# psc3m6 register map
Vendor: Infineon Technologies; Series: PSC3M6; File version: 1.0
CPU: CM33 r0p1, little endian, MPU, FPU, DSP, VTOR, 3 interrupt priority bits, 167 interrupts
Registers are 32-bit, read-write, reset 0x0 unless marked. A register's access mark holds for its fields unless they carry their own. Offsets are from the block's base; [hi:lo] are bit positions; lines under a group give offsets from that group; <NAME> marks a mode.

## I3C0 (part 2 of 3) — I3C controller top
Base 0x42C10000
0x00 CORE group — registers in I3C IP core
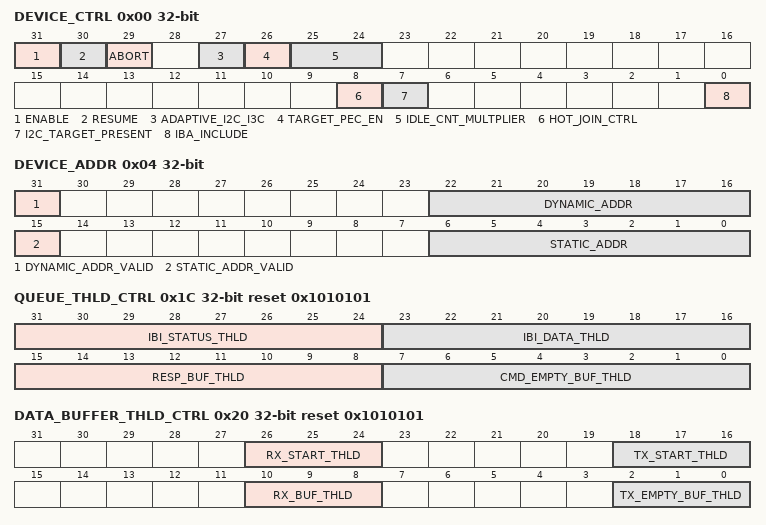
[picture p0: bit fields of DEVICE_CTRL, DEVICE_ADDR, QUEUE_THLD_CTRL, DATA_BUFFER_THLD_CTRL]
  0x00 DEVICE_CTRL — Device Control Register
    [31] ENABLE — I3C Enable Controls whether or not I3C functionality is enabled. When functioning as the Active Controller, software can write to this register to request to disable the I3C block. However, the block may not get disabled immediately and is 'Disabled' after commands in the Command queue (if any) are executed leading to a STOP condition on the bus and Controller FSM is in IDLE state (as indicated by PRESENT_STATE Register). When functioning as a Target, software can write to this register to request to disable the I3C block. However, the disable happens after the ongoing transfer is completed on the I3C bus. Software can read back 1'b0 from this field once disabling of I3C is completed. After power on reset, the software can enable I3C Secondary Controller or Target functionality by programming this bit to 1'b1. However the I3C bus interface of the block will respond to transfer on the bus, only after it observes Bus Available condition for BUS_AVAILABLE_TIME*IDLE_CNT_MULTPLIER counts of pclk period. The successful completion of Enable/Disable of the block depends on availability of SCL to the controller at the time of performing this operation, and hence may not happen instantly. Values: 0x0: Disables the I3C controller. 0x1: Enables the I3C controller.
    [30] RESUME — I3C Resume This bit is used to resume the I3C block after it goes to the Halt state. When functioning as the Active Controller, the block goes to the halt state (as indicated in PRESENT_STATE Register) due to any type of error in the transfer (the type of error is indicated by ERR_STATUS field in the RESPONSE_QUEUE_PORT register). After the block goes to the Halt state, the application has to write 1'b1 to this bit to resume. This bit is auto-cleared once the block resumes the transfers by initiating the next command. When functioning as a Target, the block goes to the halt state due to following conditions: 1 => Any type of error in the transfer (the type of error is indicated by ERR_STATUS field in the RESPONSE_QUEUE_PORT register) 2 => MRL Register updated by the Active Controller through SETMRL CCC. After the device has gone to halt state, the application has to take necessary action to handle the error condition and then write 1'b1 to this bit to resume the controller. This bit is auto-cleared once the controller is ready to accept new transfers.
    [29] ABORT — I3C Abort. This bit is only valid when this I3C Device is functioning as the Active Controller. This bit allows this device to relinquish the I3C Bus before completing the issued transfer. In response to an ABORT request, the Controller issues the STOP condition after the complete data byte is transferred or received. This bit is auto-cleared once the transfer is aborted and the controller issues a 'Transfer Abort' interrupt.
    [27] ADAPTIVE_I2C_I3C — Hot-Join Control for Adaptive I2C/I3C Mode This bit is only valid when this I3C Device is functioning as a Target. In Adaptive Mode, this bit is used to enable some features of this target device. This bit is cleared automatically if the controller determines the mode as I3C. Values: 0x0: The device initiates a Hot-Join without determining the bus mode and assuming itself to be on I3C bus. 0x1: The device initiates a Hot-Join request only after it has switched to I3C mode of operation.
    [26] TARGET_PEC_EN
    [25:24] IDLE_CNT_MULTPLIER — Idle count multiplier. This bit is only valid when this I3C Device is functioning as a Target. After power-on reset, this Target is enabled only after it sees both SDA and SCL lines idle for a specified time. This idle time is calculated by multipliying IDLE_CNT_MULTPLIER with BUS_AVAILABLE_TIME field in the BUS_FREE_AVAIL_TIMING register. Values: 0x00: BUS_AVAILABLE_TIME * 1 0x01: BUS_AVAILABLE_TIME * 2 0x10: BUS_AVAILABLE_TIME * 4 0x11: BUS_AVAILABLE_TIME * 8
    [8] HOT_JOIN_CTRL — Hot-Join ACK/NACK Control This bit is only valid when this I3C Device is functioning as the Active Controller. This bit acts as a global control to ACK/NACK the Hot-Join request from the devices. The Active Controller ACK/NACKs the Hot-Join request from other devices connected on the I3C Bus, based on programming of this bit. Values: 0x0: ACK the Hot-Join request. 0x1: NACK and send broadcast CCC(auto-disable) to disable Hot-join.
    [7] I2C_TARGET_PRESENT — <HIDDEN>
    [0] IBA_INCLUDE — I3C Broadcast Address Include. This bit is only valid when this I3C Device is functioning as the Active Controller. This bit is used to include the I3C broadcast address (0x7E) in private transfers. Note: If the I3C broadcast address is not included in private transfers, In-band Interrupts (IBI) driven from Targets might not win address arbitration and IBIs will get delayed. Values: 0x0: I3C Broadcast Address is not included in Private Transfers 0x1: I3C Broadcast Address is included in Private Transfers
  0x04 DEVICE_ADDR — Device Address Register
    [31] DYNAMIC_ADDR_VALID — Dynamic Address Valid This bit is used to control whether the DYNAMIC_ADDR is valid or not. =>When functioning as the Primary Controller, the user/application must set this bit to 1 along with the DYNAMIC_ADDR. =>When functioning as a Target, the block sets this bit to 1 when the Active Controller assigns the Dynamic address during ENTDAA or SETDASA mechanism. + Values: 0x0: Dynamic Address is invalid 0x1: Dynamic Address is valid
    [22:16] DYNAMIC_ADDR — Device Dynamic Address. This field is used to program the Device Dynamic Address. The block uses this address for I3C transfers. => When functioning as the Primary Controller, the user/application must program the Dynamic Address. => When functioning as a Target, the Active Controller assigns this address during ENTDAA or SETDASA procedures.
    [15] STATIC_ADDR_VALID — Static Address Valid. This field is only valid when this I3C Device is functioning as a Target. Values: 0x0: Static Address in STATIC_ADDR field is invalid 0x1: Static Address in STATIC_ADDR field is valid
    [6:0] STATIC_ADDR — Device Static Address. This field is only valid when this I3C Device is functioning as a Target. The device uses this address to respond to SETDASA CCC Command to get the Dynamic Address if static address is valid (STATIC_ADDRESS_VALID must be set to 1).
  0x0C COMMAND_QUEUE_PORT wo reset not defined
    [31:0] COMMAND — 32-bit Command
  0x10 RESPONSE_QUEUE_PORT ro
    [31:0] RESPONSE — 32-bit Response
  0x14 TX_RX_DATA_PORT — Transmit/Receive Data Port Register
    [31:0] TX_RX_DATA_PORT — Transmit Data Port for write access and Receive Data Port for read access. This field is mapped to the TX Data Buffer when writing and to the RX Data Buffer when reading. The data is always packed in 4-byte aligned data words. If the command length is not aligned to the 4-bytes, then the additional data bytes have to be ignored.
  0x18 IBI_QUEUE_DATA ro — In-Band Interrupt Queue Data Register
    [31:0] IBI_DATA — In-Band Interrupt Data This register is mapped to the IBI Queue. The IBI Data is always packed in 4-byte aligned and put to the IBI Queue. If the incoming data is not aligned to the 4-bytes, then there are unused bytes in the end location of the IBI transfer.
  0x1C QUEUE_THLD_CTRL reset 0x1010101 — Queue Threshold Control Register
    [31:24] IBI_STATUS_THLD — In-Band Interrupt Status Threshold Value. This field controls the number of IBI status entries (or greater) in the IBI queue that trigger the IBI_THLD_STAT interrupt. Every In Band Interrupt received (with or without Payload) by the block generates an IBI status. The application should program only valid values. NOTE: The valid value is only 0 if IBI with payload is selected in the configuration. Values: 0x0 <= N < 16: Interrupt will trigger when queue has N+1 valid entries.
    [23:16] IBI_DATA_THLD
    [15:8] RESP_BUF_THLD — Response Buffer Threshold Value. Controls the minimum number of valid entries in the Response Queue that trigger the RESP_READY_STAT_INTR interrupt. The application should programs only valid values. Values: 0x0 <= N < 8: Interrupt will trigger when queue has N+1 valid entries.
    [7:0] CMD_EMPTY_BUF_THLD — Command Buffer Empty Threshold Value Controls the minimum number of empty locations in the Command Queue that trigger the CMD_QUEUE_READY_STAT interrupt. The application should programs only valid values. Values: 0x0: Interrupt will trigger when the queue is completely empty 0x0 < N < 16: Interrupt will trigger when queue has N empty locations.
  0x20 DATA_BUFFER_THLD_CTRL reset 0x1010101 — Data Buffer Threshold Control Register
    [26:24] RX_START_THLD — Receive Start Threshold Value. When functioning as the Active Controller, when the controller is set up to initiate a read transfer, it waits until either one of the conditions are met before it initiates the read transfer on the I3C Interface. => Data length (as specified in the command) number of locations are empty in the Receive FIFO. => Threshold number of locations (or more) are empty in the Receive FIFO. When functioning as a Target, the block ACKs a write request from the Active Controller only if threshold number of empty locations(or more) are available in its receive buffer. The supported values for RX_START_THLD are: 0x0: Threshold of at least 1 empty entry 0x1: Threshold of at least 4 empty entries 0x2: Threshold of at least 8 empty entries 0x3: Threshold of at least 16 empty entries 0x4: Threshold of at least 32 empty entries 0x5: Threshold of at least 64 empty entries
    [18:16] TX_START_THLD — Transfer Start Threshold Value. When functioning as the Active Controller, when the Controller is set up to initiate a write transfer, it waits until either one of the following conditions are met before it initiates the write transfer on the I3C Interface. => Data length (as specified in the command) number of locations are filled in the TX FIFO. => Threshold number of entries (or more) are available in the TX FIFO When functioning as a Target, the Target ACKs a read request from the Active Controller only if either one of the following conditions are met. => Data length (as specified in the command) number of locations are filled in the Transmit FIFO => Threshold number of entries (or more) are available in the Transmit FIFO Supported values: 0x0: Threshold of at least 1 valid entry 0x1: Threshold of at least 4 valid entries 0x2: Threshold of at least 8 valid entries 0x3: Threshold of at least 16 valid entries 0x4: Threshold of at least 32 valid entries 0x5: Threshold of at least 64 valid entries
    [10:8] RX_BUF_THLD — Receive Buffer Threshold Value. This field controls the number of valid entries (or above) in the RX FIFO that trigger the RX_THLD_STAT interrupt. If the programmed value is greater than the buffer depth, then threshold is set to IC_RX_BUF_DEPTH. Supported values: 0x0: Interrupt triggers with at least 1 valid entry 0x1: Interrupt triggers with at least 4 valid entries 0x2: Interrupt triggers with at least 8 valid entries 0x3: Interrupt triggers with at least 16 valid entries 0x4: Interrupt triggers with at least 32 valid entries 0x5: Interrupt triggers with at least 64 valid entries
    [2:0] TX_EMPTY_BUF_THLD — Transmit Buffer Empty Threshold Value This field controls the number of empty locations (or above) in the TX FIFO that trigger the TX_THLD_STAT interrupt. If the programmed value is greater than the buffer depth, then threshold is set to IC_TX_BUF_DEPTH. Supported values: 0x0: Interrupt triggers with at least 1 empty entry 0x1: Interrupt triggers with at least 4 empty entries 0x2: Interrupt triggers with at least 8 empty entries 0x3: Interrupt triggers with at least 16 empty entries 0x4: Interrupt triggers with at least 32 empty entries 0x5: Interrupt triggers with at least 64 empty entries
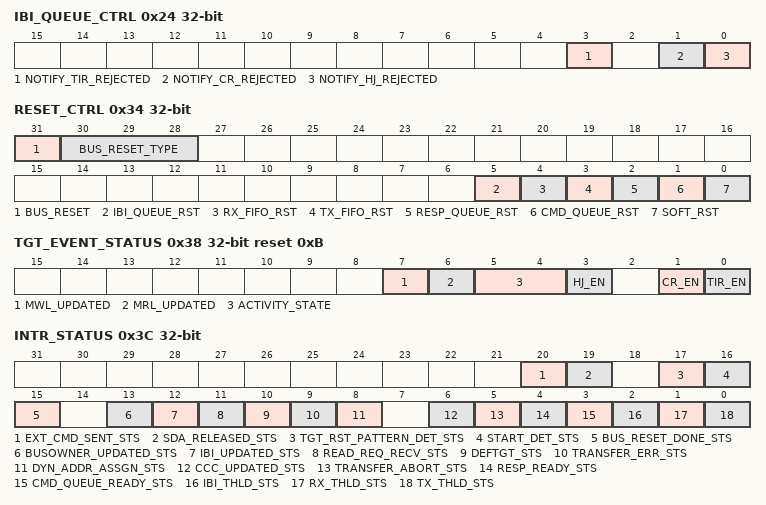
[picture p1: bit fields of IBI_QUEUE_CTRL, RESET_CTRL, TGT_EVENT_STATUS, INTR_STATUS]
  0x24 IBI_QUEUE_CTRL — IBI Queue Control Register
    [3] NOTIFY_TIR_REJECTED — Notify Rejected Target Interrupt Request Control. This bit is only valid when this I3C Device is functioning the Active Controller, and is used to suppress reporting to the application about rejected Target Interrupt Request. Values: 0x0: Disables passing the IBI Status to the IBI FIFO (hence not notifying the application) when a Target Interrupt Request is NACKed and auto-disabled based on the IBI_TIR_REQ_REJECT Register. 0x1: Enables writing the IBI Status to the IBI FIFO (hence notifying the application) when a Target Interrupt Request is NACKed and auto-disabled based on the IBI_TIR_REQ_REJECT Register.
    [1] NOTIFY_CR_REJECTED — Notify Rejected Controller Role Request (CR) Control. This bit is only valid when this I3C Device is functioning the Active Controller, and is used to suppress reporting to the application about Controller Role Request (CR) rejected. Values: 0x0: Disable passing the IBI Status to the IBI FIFO (hence not notifying the application) when a CR Request is NACKed and auto-disabled based on the IBI_CR_REQ_REJECT Register. 0x1: Enable writing the IBI Status to the IBI FIFO (hence notifying the application) when a CR Request is NACKed and auto-disabled based on the IBI_CR_REQ_REJECT Register.
    [0] NOTIFY_HJ_REJECTED — Notify Rejected Hot-Join Control. This bit is only valid when this I3C Device is functioning the Active Controller, and is used to suppress reporting to the application about Hot-Join request rejected (NACK and Auto Disable). Values: 0x0: Disable passing the IBI Status to the IBI FIFO (hence not notifying the application) when a HJ Request is NACKed and auto-disabled based on the DEVICE_CTRL.HOT_JOIN_CTRL. 0x1: Enable writing the IBI Status to the IBI FIFO (hence notifying the application) when a HJ Request is NACKed and auto-disabled based on the DEVICE_CTRL.HOT_JOIN_CTRL.
  0x34 RESET_CTRL — Reset Control Register
    [31] BUS_RESET — Write 1'b1 to this bit to exercise Bus Reset Reset Pattern Generation based on Bus Reset Type selection. This bit is cleared automatically once the Bus Reset Pattern Generation is completed.
    [30:28] BUS_RESET_TYPE
    [5] IBI_QUEUE_RST — IBI Queue Software Reset. This bit is only valid when functioning as the Active Controller. Write 0x1 to this bit to exercise IBI Queue reset. This bit is cleared automatically once the IBI Queue reset is completed. Before the reset is completed, write accesses and read accesses to the other registers will return a bus error.
    [4] RX_FIFO_RST — Receive Buffer Software Reset. Write 0x1 to this bit to exercise Receive Buffer reset This bit is cleared automatically once the Receive buffer reset is completed. Before the reset is completed, write accesses and read accesses to the other registers will return a bus error.
    [3] TX_FIFO_RST — Transmit Buffer Software Reset. Write 0x1 to this bit to exercise Transmit Buffer reset. This bit is cleared automatically once the Transmit Buffer reset is completed. Before the reset is completed, write accesses and read accesses to the other registers will return a bus error.
    [2] RESP_QUEUE_RST — Response Queue Software Reset. Write 1'b1 to this bit to exercise Response Queue reset. This bit is cleared automatically once the Response Queue reset is completed. Before the reset is completed, write accesses and read accesses to the other registers will return a bus error.
    [1] CMD_QUEUE_RST — Command Queue Software Reset. Write 0x1 to this bit to exercise Command Queue reset. This bit is cleared automatically once the Command Queue reset is completed. Before the reset is completed, write accesses and read accesses to the other registers will return a bus error.
    [0] SOFT_RST — Core Software Reset. Write 0x1 to this bit to exercise software reset. This will trigger an internal procedure that resets all Buffers - RX, TX, CMD, and Response. This bit is cleared automatically once the core reset is completed. Before the reset is completed, write accesses and read accesses to the other registers will return a bus error.
  0x38 TGT_EVENT_STATUS reset 0xB — Target Event Status Register
    [7] MWL_UPDATED write-1-clears — MWL Updated Status. This bit indicates a SETMWL CCC is received by the Target. The updated MWL value can be read from TGT_MAX_LEN register. This status can be cleared by writing 0x1 to this field after reading the updated MWL.
    [6] MRL_UPDATED write-1-clears — MRL Updated Status. This bit indicates a SETMRL CCC is received by the Target. The updated MRL value can be read from TGT_MAX_LEN register. This status can be cleared by writing 0x1 to this field after reading the updated MRL.
    [5:4] ACTIVITY_STATE ro — Activity State Status This bit reflects the Activity State of this Target set by the Active Controller. Values: 0x0: ENTAS0 0x1: ENTAS1 0x2: ENTAS2 0x3: ENTAS3
    [3] HJ_EN — Hot-Join Interrupt Enable. This bit is only valid when this I3C Device is functioning as a Target, and reflects whether the Hot-Join Request Interrupts are allowed on the I3C bus or not. The Target application can choose to Disable HJ Capability of the Target controller (if selected) by setting this field to 0 before 'Enabling' the block. When done so, the Target will not initiate Hot Join and will take part in Address Assignment without initiating Hot Join. If this field is NOT set to 0 by the Target application, it can be set or cleared by the I3C Controller via ENEC or DISEC CCCs. Once Disabled by software, CCCs do not have any effect on this field.
    [1] CR_EN ro — Controller Role Request (CR) Enable. This bit is only valid when this I3C Device is functioning as a Target, and reflects whether the controller can initiate the Controller Role Request (CR) on the I3C bus or not. Usually, this bit is set or cleared by the Active Controller through ENEC or DISEC CCC.
    [0] TIR_EN ro — Target Interrupt Request Enable. This bit is only valid when this I3C Device is functioning as a Target, and reflects whether the block can initiate the TIR on the I3C bus or not. Usually, this bit is set or cleared by the Active Controller through ENEC or DISEC CCC.
  0x3C INTR_STATUS — Interrupt Status Register
    [20] EXT_CMD_SENT_STS write-1-clears — EXT_CMD_REG_x has finished Status. This field is used only in target mode of operation. This interrupt is generated if Read Transfer has finished in the EXT_CMD_REG_x registers. This interrupt is cleared automatically when register EXT_CMD_VLD_STAT is read
    [19] SDA_RELEASED_STS write-1-clears — SDA Released from Stuck state Status. This field is used only in target mode of operation. This interrupt is generated if the SCL was not changed for the prescribed amount of time defined by RELEASE_SDA_TIMING register. This bit can be cleared by writing 1'b1
    [17] TGT_RST_PATTERN_DET_STS write-1-clears — Target Reset Pattern Detection Interrupt This field is used only when functioning as a Target. This interrupt is generated when the Target Reset pattern is detected.
    [16] START_DET_STS write-1-clears — START Detection Interrupt. This field is used only when functioning as a Target and indicates that a START has been detected. This interrupt is provided for the user/application (in CCR mode) to decide whether the NCR has taken over the ownership after the bus handover was completed successfully to move to Target mode. And to reset the reset action configured by the RSTACT CCC. This bit can be cleared by writing 1'b1.
    [15] BUS_RESET_DONE_STS write-1-clears — Bus Reset Pattern Generation Done Status This field is used only when functioning as a Controller. This interrupt is generated when the requested Bus Reset Pattern Generation is completed. This bit can be cleared by writing 1'b1.
    [13] BUSOWNER_UPDATED_STS write-1-clears — This interrupt is set when the block changes from being the Active Controller to a Secondary Controller/Target or vice versa. This bit can be cleared by writing 0x1.
    [12] IBI_UPDATED_STS write-1-clears — IBI status is updated. This field is used only when functioning as a Target. It indicates that the IBI request initiated through TIR request register is addressed and status is updated.
    [11] READ_REQ_RECV_STS write-1-clears — Read Request Received. This field is used only when functioning as a Target. Read Request received from the Active Controller when CMDQ is empty. This bit can be cleared by writing 0x1.
    [10] DEFTGT_STS write-1-clears — Define Target CCC Received Status. This interrupt is generated if DEFTGTS CCC is received. This bit can be cleared by writing 0x1.
    [9] TRANSFER_ERR_STS write-1-clears — Transfer Error Status. This interrupt is generated if any error occurs during transfer. The error type is specified in the response packet associated with the command (in ERR_STATUS field of RESPONSE_QUEUE_PORT register). This bit can be cleared by writing 0x1.
    [8] DYN_ADDR_ASSGN_STS write-1-clears — Dynamic Address Assigned Status This field is used only in Target mode of operation. This interrupt is generated when the device's Dynamic Address is assigned through SETDASA, SETAASA, SETNEWDA or ENTDAA CCC. This bit can be cleared by writing 0x1
    [6] CCC_UPDATED_STS write-1-clears — CCC Table Updated Status. This field is used only when functioning as a Target. This interrupt is generated if any of the CCC registers are updated by the I3C Controller through CCC commands. This interrupt can be cleared by writing 0x1.
    [5] TRANSFER_ABORT_STS write-1-clears — Transfer Abort Status. This field is used only when functioning as the Active Controller,. This interrupt is generated if the transfer is aborted. This interrupt can be cleared by writing 0x1.
    [4] RESP_READY_STS ro — Response Queue Ready Status. This interrupt is generated when number of entries in the response queue is greater than or equal to the threshold value specified by the RESP_BUF_THLD field in the QUEUE_THLD_CTRL register. This interrupt is cleared automatically when the number of entries in the response buffer is less than the threshold value specified.
    [3] CMD_QUEUE_READY_STS ro — Command Queue Ready. This interrupt is generated when number of empty locations in the command queue is greater than or equal to the threshold value specified by the CMD_EMPTY_BUF_THLD field in the QUEUE_THLD_CTRL register. This interrupt is cleared automatically when the number of empty locations in the command buffer is less than the threshold value specified.
    [2] IBI_THLD_STS ro — IBI Buffer Threshold Status. This field is only used when the block is functioning as the Active Controller. This interrupt is generated when the number of entries in the IBI buffer is greater than or equal to the threshold value specified by the IBI_BUF_THLD field in the QUEUE_THLD_CTRL register. This interrupt is cleared automatically when the number of entries in IBI buffer is less than the threshold value specified.
    [1] RX_THLD_STS ro — Receive Buffer Threshold Status. This interrupt is generated when number of entries in the receive buffer is greater than or equal to threshold value specified by the RX_BUF_THLD field in the DATA_BUFFER_THLD_CTRL register. This interrupt is cleared automatically when the number of entries in receive buffer is less than the threshold value specified.
    [0] TX_THLD_STS ro — Transmit Buffer Threshold Status. This interrupt is generated when the number of empty locations in the transmit buffer is greater than or equal to the threshold value specified by the TX_EMPTY_BUF_THLD field in the DATA_BUFFER_THLD_CTRL register. This interrupt is cleared automatically when the number of empty locations in transmit buffer is less than threshold value specified.
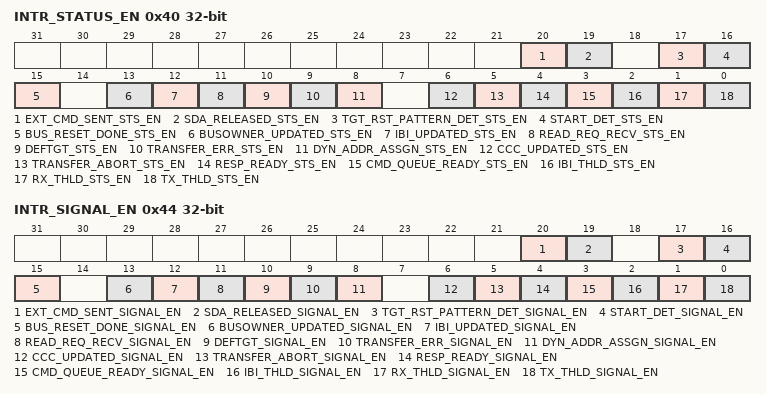
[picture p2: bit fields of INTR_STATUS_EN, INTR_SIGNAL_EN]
  0x40 INTR_STATUS_EN — Interrupt Status Enable Register.
    [20] EXT_CMD_SENT_STS_EN — EXT_CMD_REG_x has finished Signal Enable. This field is used when operating as a Target.
    [19] SDA_RELEASED_STS_EN — SDA Released from Stuck state Status Enable. This field is used in target mode of operation
    [17] TGT_RST_PATTERN_DET_STS_EN — Target Reset Pattern Detection Interrupt Status Enable
    [16] START_DET_STS_EN — START Detection Interrupt Status Enable
    [15] BUS_RESET_DONE_STS_EN — Bus Reset Pattern Generation Done Status Enable
    [13] BUSOWNER_UPDATED_STS_EN — Bus owner Updated Status Enable
    [12] IBI_UPDATED_STS_EN — IBI Updated Status Enable This field is only valid when functioning as a Target.
    [11] READ_REQ_RECV_STS_EN — Read Request Received Status Enable This field is only valid when functioning as a Target.
    [10] DEFTGT_STS_EN — Define Target CCC Received Status Enable
    [9] TRANSFER_ERR_STS_EN — Transfer Error Status Enable
    [8] DYN_ADDR_ASSGN_STS_EN — Dynamic Address Assigned Status Enable This field is only valid when functioning as a Target.
    [6] CCC_UPDATED_STS_EN — CCC Table Updated Status Enable. This field is only valid when functioning as a Target.
    [5] TRANSFER_ABORT_STS_EN — Transfer Abort Status Enable. This field is only valid when functioning as the Active Controller.
    [4] RESP_READY_STS_EN — Response Queue Ready Status Enable
    [3] CMD_QUEUE_READY_STS_EN — Command Queue Ready Status Enable
    [2] IBI_THLD_STS_EN — IBI Buffer Threshold Status Enable This field is only valid when functioning aa the Active Controller.
    [1] RX_THLD_STS_EN — Receive Buffer Threshold Status Enable
    [0] TX_THLD_STS_EN — Transmit Buffer Threshold Status Enable
  0x44 INTR_SIGNAL_EN — Interrupt Signal Enable Register
    [20] EXT_CMD_SENT_SIGNAL_EN
    [19] SDA_RELEASED_SIGNAL_EN — SDA Released from Stuck state Signal Enable. This field is used in target mode of operation
    [17] TGT_RST_PATTERN_DET_SIGNAL_EN — Target Reset Pattern Detection Interrupt Signal Enable
    [16] START_DET_SIGNAL_EN — START Detection Interrupt Signal Enable
    [15] BUS_RESET_DONE_SIGNAL_EN — Bus Reset Pattern Generation Done Signal Enable
    [13] BUSOWNER_UPDATED_SIGNAL_EN — Bus owner Updated Signal Enable
    [12] IBI_UPDATED_SIGNAL_EN — IBI Updated Signal Enable This field is only valid when functioning as a Target.
    [11] READ_REQ_RECV_SIGNAL_EN — Read Request Received Signal Enable This field is only valid when functioning as a Target.
    [10] DEFTGT_SIGNAL_EN — Define Target CCC Received Signal Enable
    [9] TRANSFER_ERR_SIGNAL_EN — Transfer Error Signal Enable
    [8] DYN_ADDR_ASSGN_SIGNAL_EN — Dynamic Address Assigned Signal Enable This field is only valid when functioning as a Target.
    [6] CCC_UPDATED_SIGNAL_EN — CCC Table Updated Signal Enable. This field is only valid when functioning as a Target.
    [5] TRANSFER_ABORT_SIGNAL_EN — Transfer Abort Signal Enable. This field is only valid when functioning as the Active Controller.
    [4] RESP_READY_SIGNAL_EN — Response Queue Ready Signal Enable
    [3] CMD_QUEUE_READY_SIGNAL_EN — Command Queue Ready Signal Enable
    [2] IBI_THLD_SIGNAL_EN — IBI Buffer Threshold Signal Enable This field is only valid when functioning aa the Active Controller.
    [1] RX_THLD_SIGNAL_EN — Receive Buffer Threshold Signal Enable
    [0] TX_THLD_SIGNAL_EN — Transmit Buffer Threshold Signal Enable
